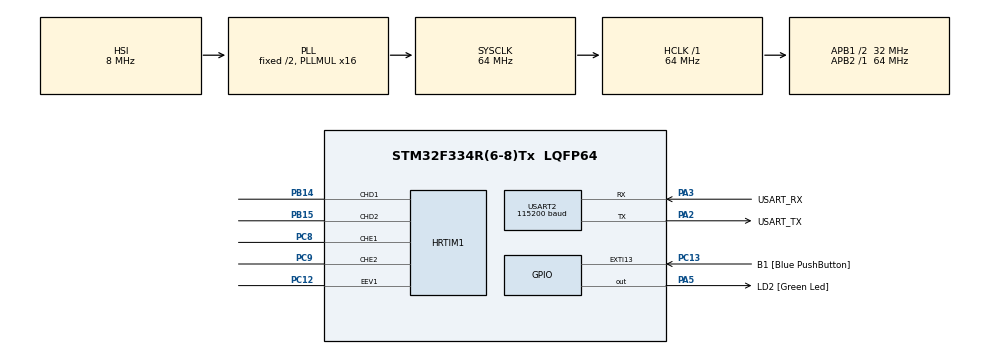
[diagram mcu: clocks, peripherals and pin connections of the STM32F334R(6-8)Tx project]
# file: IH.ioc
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Dma.Request0=USART2_RX
Dma.Request1=USART2_TX
Dma.USART2_RX.0.Direction=DMA_PERIPH_TO_MEMORY
Dma.USART2_RX.0.Instance=DMA1_Channel6
Dma.USART2_RX.0.MemDataAlignment=DMA_MDATAALIGN_BYTE
Dma.USART2_RX.0.MemInc=DMA_MINC_ENABLE
Dma.USART2_RX.0.Mode=DMA_NORMAL
Dma.USART2_RX.0.PeriphDataAlignment=DMA_PDATAALIGN_BYTE
Dma.USART2_RX.0.PeriphInc=DMA_PINC_DISABLE
Dma.USART2_RX.0.Priority=DMA_PRIORITY_LOW
Dma.USART2_TX.1.Direction=DMA_MEMORY_TO_PERIPH
Dma.USART2_TX.1.Instance=DMA1_Channel7
Dma.USART2_TX.1.MemDataAlignment=DMA_MDATAALIGN_BYTE
Dma.USART2_TX.1.MemInc=DMA_MINC_ENABLE
Dma.USART2_TX.1.Mode=DMA_NORMAL
Dma.USART2_TX.1.PeriphDataAlignment=DMA_PDATAALIGN_BYTE
Dma.USART2_TX.1.PeriphInc=DMA_PINC_DISABLE
Dma.USART2_TX.1.Priority=DMA_PRIORITY_LOW
HRTIM1.CaptureUnit1-Output_TD1TD2=__NULL
HRTIM1.CaptureUnit1-Output_TE1TE2=__NULL
HRTIM1.CompareUnit1-MasterTimer=HRTIM_COMPAREUNIT_1
HRTIM1.CompareUnit1-Output_TD1TD2=HRTIM_COMPAREUNIT_1
HRTIM1.CompareUnit1-Output_TE1TE2=HRTIM_COMPAREUNIT_1
HRTIM1.CompareUnit2-MasterTimer=HRTIM_COMPAREUNIT_2
HRTIM1.CompareValue1-MasterTimer=20000
HRTIM1.CompareValue2-MasterTimer=30000
HRTIM1.DeadTimeInsertion-Output_TD1TD2=HRTIM_TIMDEADTIMEINSERTION_ENABLED
HRTIM1.DeadTimeInsertion-Output_TE1TE2=HRTIM_TIMDEADTIMEINSERTION_ENABLED
HRTIM1.FallingLock-Output_TD1TD2=HRTIM_TIMDEADTIME_FALLINGLOCK_READONLY
HRTIM1.FallingLock-Output_TE1TE2=HRTIM_TIMDEADTIME_FALLINGLOCK_READONLY
HRTIM1.FallingSignLock-Output_TD1TD2=HRTIM_TIMDEADTIME_FALLINGSIGNLOCK_READONLY
HRTIM1.FallingSignLock-Output_TE1TE2=HRTIM_TIMDEADTIME_FALLINGSIGNLOCK_READONLY
HRTIM1.FallingValue-Output_TD1TD2=359
HRTIM1.FallingValue-Output_TE1TE2=359
HRTIM1.HalfModeEnable-MasterTimer=HRTIM_HALFMODE_DISABLED
HRTIM1.HalfModeEnable-Output_TD1TD2=HRTIM_HALFMODE_ENABLED
HRTIM1.HalfModeEnable-Output_TE1TE2=HRTIM_HALFMODE_ENABLED
HRTIM1.IdleLevel1-Output_TD1TD2=HRTIM_OUTPUTIDLELEVEL_ACTIVE
HRTIM1.IdleLevel1-Output_TE1TE2=HRTIM_OUTPUTIDLELEVEL_ACTIVE
HRTIM1.InterruptRequests1-Output_TD1TD2=HRTIM_TIM_IT_NONE
HRTIM1.ModeTimeBase-MasterTimer=HRTIM_MODE_CONTINUOUS
HRTIM1.ModeTimeBase-Output_TD1TD2=HRTIM_MODE_SINGLESHOT_RETRIGGERABLE
HRTIM1.ModeTimeBase-Output_TE1TE2=HRTIM_MODE_SINGLESHOT_RETRIGGERABLE
HRTIM1.NumberInterruptRequests-Output_TD1TD2=0
HRTIM1.NumberInterruptRequests-Output_TE1TE2=0
HRTIM1.NumberResetSource1-Output_TD1TD2=1
HRTIM1.NumberResetSource1-Output_TE1TE2=1
HRTIM1.NumberResetTrigger-Output_TD1TD2=1
HRTIM1.NumberResetTrigger-Output_TE1TE2=1
HRTIM1.NumberSetSource1-Output_TD1TD2=1
HRTIM1.NumberSetSource1-Output_TE1TE2=1
HRTIM1.NumberTriggerSource_Captureconfig1-Output_TD1TD2=1
HRTIM1.NumberUpdateTrigger-Output_TD1TD2=1
HRTIM1.NumberUpdateTrigger-Output_TE1TE2=1
HRTIM1.Periode_MASTER=50000
HRTIM1.Periode_TD=50000
HRTIM1.Periode_TE=50000
HRTIM1.PreloadEnable-MasterTimer=HRTIM_PRELOAD_ENABLED
HRTIM1.PreloadEnable-Output_TD1TD2=HRTIM_PRELOAD_ENABLED
HRTIM1.PreloadEnable-Output_TE1TE2=HRTIM_PRELOAD_ENABLED
HRTIM1.RepetitionUpdate-MasterTimer=HRTIM_UPDATEONREPETITION_ENABLED
HRTIM1.RepetitionUpdate-Output_TE1TE2=HRTIM_UPDATEONREPETITION_DISABLED
HRTIM1.ResetOutput1_Source1-Output_TD1TD2=HRTIM_OUTPUTRESET_MASTERCMP1
HRTIM1.ResetOutput1_Source1-Output_TE1TE2=HRTIM_OUTPUTRESET_TIMPER
HRTIM1.ResetTrigger1-Output_TD1TD2=HRTIM_TIMRESETTRIGGER_MASTER_CMP1
HRTIM1.ResetTrigger1-Output_TE1TE2=HRTIM_TIMRESETTRIGGER_MASTER_CMP2
HRTIM1.RisingLock-Output_TD1TD2=HRTIM_TIMDEADTIME_RISINGLOCK_READONLY
HRTIM1.RisingLock-Output_TE1TE2=HRTIM_TIMDEADTIME_RISINGLOCK_READONLY
HRTIM1.RisingSignLock-Output_TD1TD2=HRTIM_TIMDEADTIME_RISINGSIGNLOCK_READONLY
HRTIM1.RisingSignLock-Output_TE1TE2=HRTIM_TIMDEADTIME_RISINGSIGNLOCK_READONLY
HRTIM1.RisingValue-Output_TD1TD2=359
HRTIM1.RisingValue-Output_TE1TE2=359
HRTIM1.Sensitivity_EEV1=HRTIM_EVENTSENSITIVITY_RISINGEDGE
HRTIM1.SetOutput1_Source1-Output_TD1TD2=HRTIM_OUTPUTSET_TIMCMP1
HRTIM1.SetOutput1_Source1-Output_TE1TE2=HRTIM_OUTPUTSET_TIMCMP1
HRTIM1.TriggerCapture1_Source1-Output_TD1TD2=HRTIM_CAPTURETRIGGER_EEV_1
HRTIM1.UpdateTrigger1-Output_TD1TD2=HRTIM_TIMUPDATETRIGGER_MASTER
HRTIM1.UpdateTrigger1-Output_TE1TE2=HRTIM_TIMUPDATETRIGGER_MASTER
Mcu.Family=STM32F3
Mcu.Name=STM32F334R(6-8)Tx
Mcu.Package=LQFP64
NVIC.DMA1_Channel6_IRQn=true\:0\:0\:false\:false\:true\:false\:true
NVIC.DMA1_Channel7_IRQn=true\:0\:0\:false\:false\:true\:false\:true
NVIC.PriorityGroup=NVIC_PRIORITYGROUP_0
NVIC.USART2_IRQn=true\:0\:0\:false\:false\:true\:true\:true
PA13.GPIO_Label=TMS
PA13.Mode=Serial_Wire
PA13.Signal=SYS_JTMS-SWDIO
PA14.GPIO_Label=TCK
PA14.Mode=Serial_Wire
PA14.Signal=SYS_JTCK-SWCLK
PA2.GPIO_Label=USART_TX
PA2.Mode=Asynchronous
PA2.Signal=USART2_TX
PA3.GPIO_Label=USART_RX
PA3.Mode=Asynchronous
PA3.Signal=USART2_RX
PA5.GPIO_Label=LD2 [Green Led]
PA5.Signal=GPIO_Output
PB14.Mode=Output_TD1TD2
PB14.Signal=HRTIM1_CHD1
PB15.Mode=Output_TD1TD2
PB15.Signal=HRTIM1_CHD2
PB3.GPIO_Label=SWO
PB3.Signal=SYS_JTDO-TRACESWO
PC12.GPIO_PuPd=GPIO_PULLDOWN
PC12.Mode=External_Evt_enable1
PC12.Signal=HRTIM1_EEV1
PC13.GPIO_Label=B1 [Blue PushButton]
PC13.GPIO_ModeDefaultEXTI=GPIO_MODE_IT_FALLING
PC13.Signal=GPXTI13
PC14\ /\ OSC32_IN.Mode=LSE-External-Oscillator
PC14\ /\ OSC32_IN.Signal=RCC_OSC32_IN
PC15\ /\ OSC32_OUT.GPIO_Label=RCC_OSC32_OUT
PC15\ /\ OSC32_OUT.Mode=LSE-External-Oscillator
PC15\ /\ OSC32_OUT.Signal=RCC_OSC32_OUT
PC8.Mode=Output_TE1TE2
PC8.Signal=HRTIM1_CHE1
PC9.Mode=Output_TE1TE2
PC9.Signal=HRTIM1_CHE2
PF0\ /\ OSC_IN.Mode=HSE-External-Clock-Source
PF0\ /\ OSC_IN.Signal=RCC_OSC_IN
PF1\ /\ OSC_OUT.Signal=RCC_OSC_OUT
ProjectManager.HeapSize=0x200
ProjectManager.StackSize=0x400
ProjectManager.TargetToolchain=SW4STM32
RCC.AHBFreq_Value=64000000
RCC.APB1CLKDivider=RCC_HCLK_DIV2
RCC.APB1Freq_Value=32000000
RCC.APB1TimFreq_Value=64000000
RCC.APB2Freq_Value=64000000
RCC.APB2TimFreq_Value=64000000
RCC.CortexFreq_Value=64000000
RCC.FLatency-AdvancedSettings=FLASH_LATENCY_2
RCC.HCLKFreq_Value=64000000
RCC.HRTIMSelection=RCC_HRTIM1CLK_PLLCLK
RCC.HSE_VALUE=8000000
RCC.HSI_VALUE=8000000
RCC.PLLMUL=RCC_PLL_MUL16
RCC.SYSCLKFreq_VALUE=64000000
RCC.SYSCLKSourceVirtual=RCC_SYSCLKSOURCE_PLLCLK
USART2.BaudRate=115200
USART2.VirtualMode-Asynchronous=VM_ASYNC
VP_HRTIM1_VS_hrtimMasterTimerNoOutput.Mode=MasterTimer
board=NUCLEO-F334R8

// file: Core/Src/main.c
/* USER CODE BEGIN Header */
/**
 ******************************************************************************
 * @file           : main.c
 * @brief          : Main program body
 ******************************************************************************
 * @attention
 *
 * <h2><center>&copy; Copyright (c) 2021 STMicroelectronics.
 * All rights reserved.</center></h2>
 *
 * This software component is licensed by ST under BSD 3-Clause license,
 * the "License"; You may not use this file except in compliance with the
 * License. You may obtain a copy of the License at:
 *                        opensource.org/licenses/BSD-3-Clause
 *
 ******************************************************************************
 */
/* USER CODE END Header */
#include "main.h"
#include "dma.h"
#include "hrtim.h"
#include "hrtim.h"
#include "usart.h"
#include "gpio.h"

/* USER CODE BEGIN Includes */
#include "system/comm.h"
#include "system/pidController.h"
#include "system/outputPwmController.h"
/* USER CODE END Includes */

void SystemClock_Config(void);

int main(void)
{

  /* MCU Configuration--------------------------------------------------------*/

  /* Reset of all peripherals, Initializes the Flash interface and the Systick. */
  HAL_Init();

  /* Configure the system clock */
  SystemClock_Config();

  /* Initialize all configured peripherals */
  MX_GPIO_Init();
  MX_DMA_Init();
  MX_HRTIM1_Init();
  MX_USART2_UART_Init();
  /* USER CODE BEGIN 2 */

    receptionStart();
  /* USER CODE END 2 */

  /* Infinite loop */
  /* USER CODE BEGIN WHILE */
    while (1) {
        txTask();
        rxTask();
    /* USER CODE END WHILE */

    }
}

void SystemClock_Config(void)
{
  RCC_OscInitTypeDef RCC_OscInitStruct = {0};
  RCC_ClkInitTypeDef RCC_ClkInitStruct = {0};
  RCC_PeriphCLKInitTypeDef PeriphClkInit = {0};

  /** Initializes the RCC Oscillators according to the specified parameters
  * in the RCC_OscInitTypeDef structure.
  */
  RCC_OscInitStruct.OscillatorType = RCC_OSCILLATORTYPE_HSI;
  RCC_OscInitStruct.HSIState = RCC_HSI_ON;
  RCC_OscInitStruct.HSICalibrationValue = RCC_HSICALIBRATION_DEFAULT;
  RCC_OscInitStruct.PLL.PLLState = RCC_PLL_ON;
  RCC_OscInitStruct.PLL.PLLSource = RCC_PLLSOURCE_HSI;
  RCC_OscInitStruct.PLL.PLLMUL = RCC_PLL_MUL16;
  if (HAL_RCC_OscConfig(&RCC_OscInitStruct) != HAL_OK)
  {
    Error_Handler();
  }
  /** Initializes the CPU, AHB and APB buses clocks
  */
  RCC_ClkInitStruct.ClockType = RCC_CLOCKTYPE_HCLK|RCC_CLOCKTYPE_SYSCLK
                              |RCC_CLOCKTYPE_PCLK1|RCC_CLOCKTYPE_PCLK2;
  RCC_ClkInitStruct.SYSCLKSource = RCC_SYSCLKSOURCE_PLLCLK;
  RCC_ClkInitStruct.AHBCLKDivider = RCC_SYSCLK_DIV1;
  RCC_ClkInitStruct.APB1CLKDivider = RCC_HCLK_DIV2;
  RCC_ClkInitStruct.APB2CLKDivider = RCC_HCLK_DIV1;

  if (HAL_RCC_ClockConfig(&RCC_ClkInitStruct, FLASH_LATENCY_2) != HAL_OK)
  {
    Error_Handler();
  }
  PeriphClkInit.PeriphClockSelection = RCC_PERIPHCLK_HRTIM1;
  PeriphClkInit.Hrtim1ClockSelection = RCC_HRTIM1CLK_PLLCLK;
  if (HAL_RCCEx_PeriphCLKConfig(&PeriphClkInit) != HAL_OK)
  {
    Error_Handler();
  }
}

void Error_Handler(void)
{
    __disable_irq();
    while (1) {
    }
}

/************************ (C) COPYRIGHT STMicroelectronics *****END OF FILE****/
